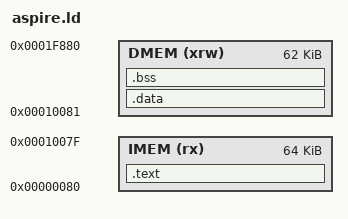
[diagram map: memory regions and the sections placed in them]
/* Based on: https://github.com/YosysHQ/picorv32/blob/master/picosoc/sections.lds */

OUTPUT_ARCH(riscv)
ENTRY(_start)

MEMORY
{
    IMEM (rx)        : ORIGIN = 0x000080, LENGTH = 0x10000 /* IMEM (program), 64 KiB */
    DMEM (xrw)       : ORIGIN = 0x010081, LENGTH = 0x0F800 /* DMEM (RAM), 62 KiB */
}

SECTIONS {
    /* The program code and other data goes into FLASH */
    .text :
    {
        . = ALIGN(4);
        *(.text.init)      /* Force init to go first in the executable */
        *(.text)           /* .text sections (code) */
        *(.text*)          /* .text* sections (code) */
        *(.rodata)         /* .rodata sections (constants, strings, etc.) */
        *(.rodata*)        /* .rodata* sections (constants, strings, etc.) */
        *(.srodata)        /* .rodata sections (constants, strings, etc.) */
        *(.srodata*)       /* .rodata* sections (constants, strings, etc.) */
        . = ALIGN(4);
        _etext = .;        /* define a global symbol at end of code */
        _sidata = _etext;  /* This is used by the startup in order to initialize the .data secion */
        KEEP(*(.text.init)) /* Force linker to keep text.init */
    } >IMEM

    /* FIXME THIS IS NOT THE CASE FOR ASPIRE */
    /* This is the initialized data section
    The program executes knowing that the data is in the RAM
    but the loader puts the initial values in the FLASH (inidata).
    It is one task of the startup to copy the initial values from FLASH to RAM. */
    .data : AT ( _sidata )
    {
        . = ALIGN(4);
        _sdata = .;        /* create a global symbol at data start; used by startup code in order to initialise the .data section in RAM */
        _ram_start = .;    /* create a global symbol at ram start for garbage collector */
        . = ALIGN(4);
        *(.data)           /* .data sections */
        *(.data*)          /* .data* sections */
        *(.sdata)           /* .sdata sections */
        *(.sdata*)          /* .sdata* sections */
        . = ALIGN(4);
        _edata = .;        /* define a global symbol at data end; used by startup code in order to initialise the .data section in RAM */
    } >DMEM

    /* Uninitialized data section */
    .bss :
    {
        . = ALIGN(4);
        _sbss = .;         /* define a global symbol at bss start; used by startup code */
        *(.bss)
        *(.bss*)
        *(.sbss)
        *(.sbss*)
        *(COMMON)

        . = ALIGN(4);
        _ebss = .;         /* define a global symbol at bss end; used by startup code */
    } >DMEM
    
    /* No heap on Aspire (currently) */
}
